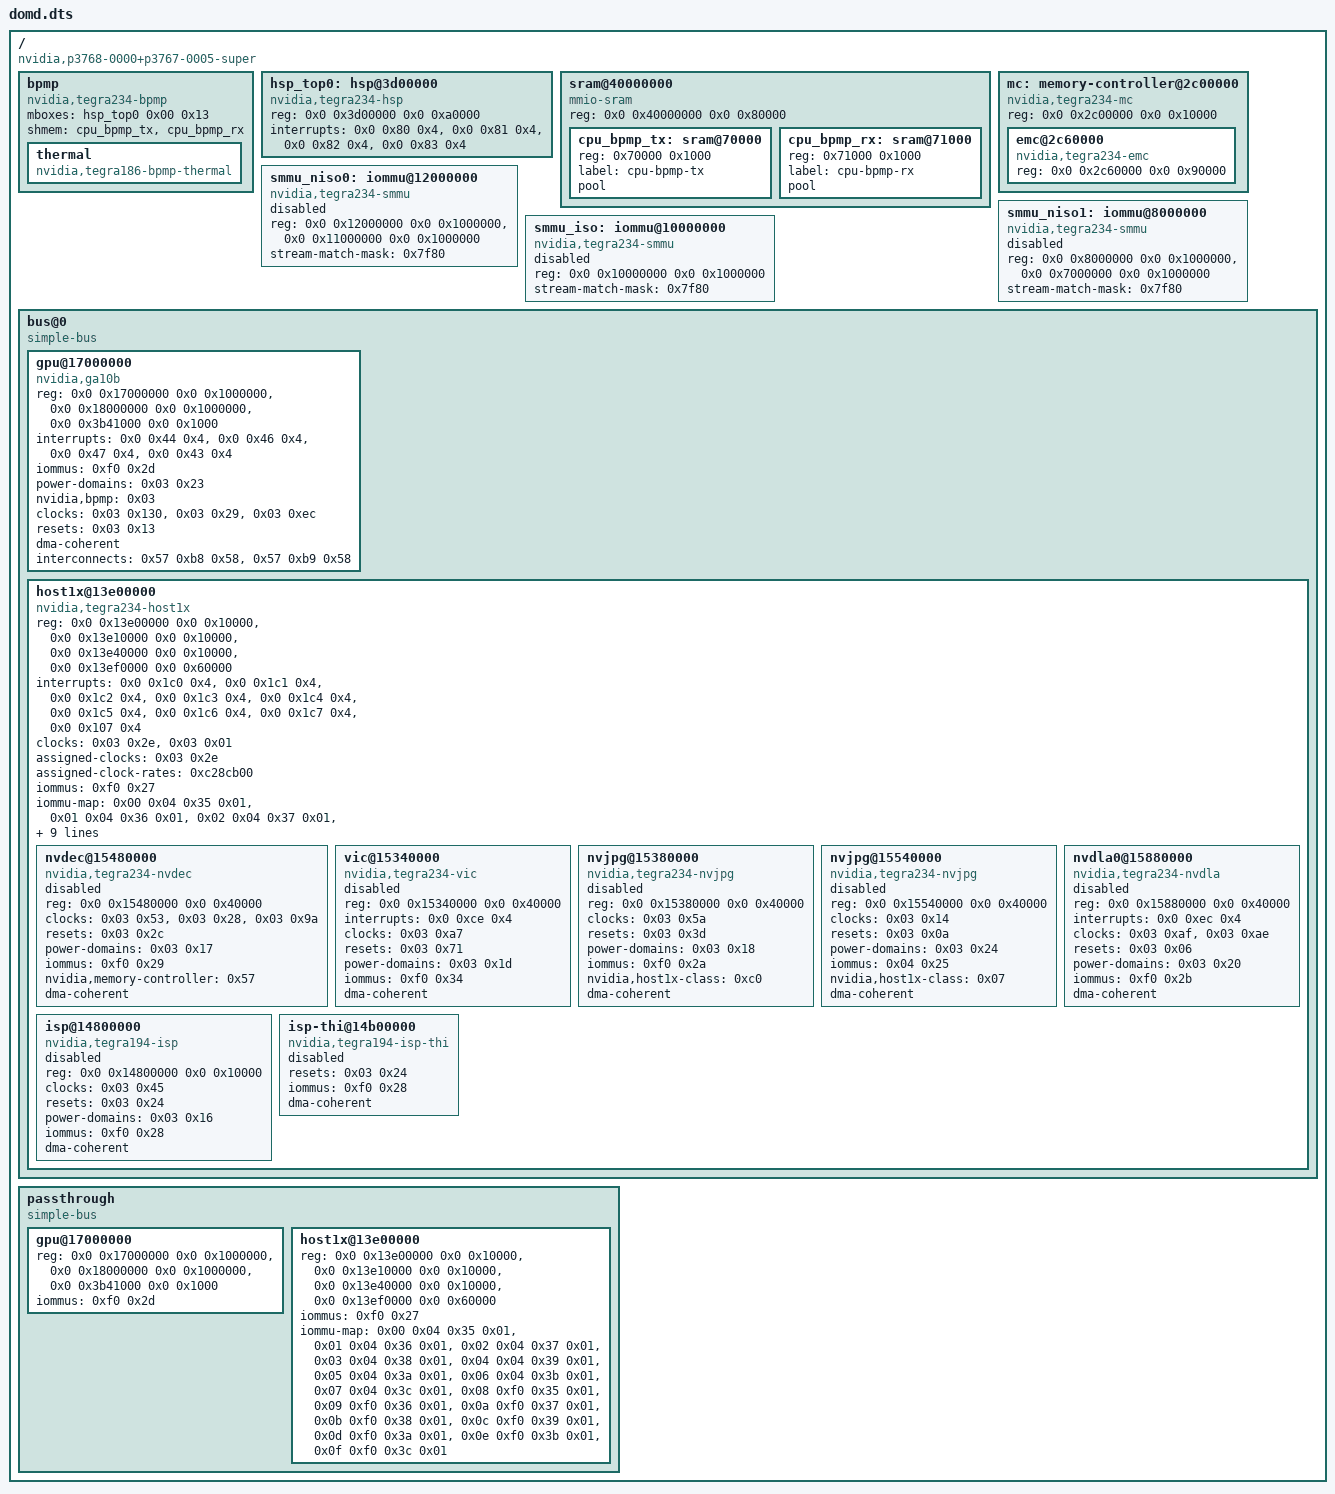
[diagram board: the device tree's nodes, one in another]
/dts-v1/;

/*
 * DomD Device Tree for GA10B GPU Passthrough — Jetson Orin Nano (tegra234)
 *
 * STRATEGY: Approach B — Stub BPMP
 *   Dom0 must pre-configure GPU (power-on, clocks, out-of-reset) before
 *   creating DomD.  GPU runs at whatever frequency Dom0 set, no DVFS.
 *
 * CHANGELOG:
 *   - Added /passthrough node (required by Xen libxl when
 *     passthrough = "enabled" is set in the domain config).
 *     Without this node xl create fails with FDT_ERR_NOTFOUND.
 */

/ {
	#address-cells = <2>;
	#size-cells = <2>;
	compatible = "nvidia,p3768-0000+p3767-0005-super",
	             "nvidia,p3767-0005",
	             "nvidia,tegra234";

	/* ================================================================
	 * BPMP — Stub / real depending on approach.
	 * Phandle 0x03 is referenced by GPU clocks/resets/power-domains.
	 * ================================================================ */
	bpmp: bpmp {
		compatible = "nvidia,tegra234-bpmp", "nvidia,tegra186-bpmp";
		#clock-cells = <1>;
		#reset-cells = <1>;
		#power-domain-cells = <1>;
		phandle = <0x03>;
		mboxes = <&hsp_top0 0x00 0x13>;
		shmem = <&cpu_bpmp_tx &cpu_bpmp_rx>;
		status = "okay";

		thermal {
			#thermal-sensor-cells = <1>;
			compatible = "nvidia,tegra186-bpmp-thermal";
		};
	};

	/* ================================================================
	 * HSP — doorbell for BPMP IPC
	 * Shared with Dom0; ensure Dom0 has released or proxied BPMP
	 * before DomD boots.
	 * ================================================================ */
	hsp_top0: hsp@3d00000 {
		compatible = "nvidia,tegra234-hsp", "nvidia,tegra194-hsp";
		reg = <0x0 0x3d00000 0x0 0xa0000>;
		interrupts = <0x0 0x80 0x4>,
		             <0x0 0x81 0x4>,
		             <0x0 0x82 0x4>,
		             <0x0 0x83 0x4>;
		interrupt-names = "shared0", "shared1", "shared2", "shared3";
		#mbox-cells = <2>;
		status = "okay";
	};

	/* ================================================================
	 * SRAM — IPC shared memory for BPMP
	 * ================================================================ */
	sram@40000000 {
		compatible = "mmio-sram";
		reg = <0x0 0x40000000 0x0 0x80000>;
		#address-cells = <1>;
		#size-cells = <1>;
		ranges = <0x0 0x0 0x40000000 0x80000>;

		cpu_bpmp_tx: sram@70000 {
			reg = <0x70000 0x1000>;
			label = "cpu-bpmp-tx";
			pool;
		};

		cpu_bpmp_rx: sram@71000 {
			reg = <0x71000 0x1000>;
			label = "cpu-bpmp-rx";
			pool;
		};
	};

	/* ================================================================
	 * Memory controller / EMC — GPU driver references these for
	 * bandwidth requests.  With stub BPMP the requests are no-ops.
	 * ================================================================ */
	mc: memory-controller@2c00000 {
		compatible = "nvidia,tegra234-mc";
		reg = <0x0 0x2c00000 0x0 0x10000>;
		#interconnect-cells = <1>;
		phandle = <0x57>;
		status = "okay";

		emc@2c60000 {
			compatible = "nvidia,tegra234-emc";
			reg = <0x0 0x2c60000 0x0 0x90000>;
			#interconnect-cells = <0>;
			phandle = <0x58>;
			status = "okay";
		};
	};

	/* ================================================================
	 * IOMMU / SMMU — reference-only, Xen owns the real hardware.
	 *
	 * These nodes MUST be disabled so the guest kernel does not
	 * probe them.  They exist only so that iommus phandle references
	 * in GPU and host1x nodes resolve correctly at DT parse time.
	 *
	 *   phandle 0x04  = NISO0 SMMU  @ 0x12000000
	 *   phandle 0xf0  = NISO1 SMMU  @ 0x08000000  (GPU SID 0x2d)
	 *   phandle 0x109 = ISO  SMMU   @ 0x10000000
	 * ================================================================ */
	smmu_niso0: iommu@12000000 {
		compatible = "nvidia,tegra234-smmu", "nvidia,smmu-500";
		reg = <0x0 0x12000000 0x0 0x1000000>,
		      <0x0 0x11000000 0x0 0x1000000>;
		#iommu-cells = <1>;
		stream-match-mask = <0x7f80>;
		phandle = <0x04>;
		status = "disabled";
	};

	smmu_niso1: iommu@8000000 {
		compatible = "nvidia,tegra234-smmu", "nvidia,smmu-500";
		reg = <0x0 0x8000000 0x0 0x1000000>,
		      <0x0 0x7000000 0x0 0x1000000>;
		#iommu-cells = <1>;
		stream-match-mask = <0x7f80>;
		phandle = <0xf0>;
		status = "disabled";
	};

	smmu_iso: iommu@10000000 {
		compatible = "nvidia,tegra234-smmu", "nvidia,smmu-500";
		reg = <0x0 0x10000000 0x0 0x1000000>;
		#iommu-cells = <1>;
		stream-match-mask = <0x7f80>;
		phandle = <0x109>;
		status = "disabled";
	};

	/* ================================================================
	 * Main bus
	 * ================================================================ */
	bus@0 {
		#address-cells = <2>;
		#size-cells = <2>;
		compatible = "simple-bus";
		ranges = <0x00 0x00 0x00 0x00 0x100 0x00>;

		/* ============================================================
		 * GPU — GA10B (Ampere) — PRIMARY PASSTHROUGH TARGET
		 *
		 * Register regions:
		 *   0x17000000  16 MB — GPU controller / GPC
		 *   0x18000000  16 MB — GPU Falcon / PMU
		 *   0x3b41000    4 KB — GPU scratch / priv ring
		 *
		 * Interrupts (SPI, so add 32):
		 *   68 (0x44) stall0  | 70 (0x46) stall1
		 *   71 (0x47) stall2  | 67 (0x43) nonstall
		 *
		 * IOMMU: SID 0x2d on NISO1 SMMU (phandle 0xf0)
		 * ============================================================ */
		gpu@17000000 {
			compatible = "nvidia,ga10b";
			reg = <0x0 0x17000000 0x0 0x1000000>,
			      <0x0 0x18000000 0x0 0x1000000>,
			      <0x0 0x3b41000  0x0 0x1000>;
			interrupts = <0x0 0x44 0x4>,
			             <0x0 0x46 0x4>,
			             <0x0 0x47 0x4>,
			             <0x0 0x43 0x4>;
			interrupt-names = "stall0", "stall1", "stall2", "nonstall";

			iommus = <0xf0 0x2d>;

			power-domains = <0x03 0x23>;
			nvidia,bpmp = <0x03>;
			clocks = <0x03 0x130>,
			         <0x03 0x29>,
			         <0x03 0xec>;
			clock-names = "sysclk", "gpc0clk", "gpc1clk";
			resets = <0x03 0x13>;
			reset-names = "gpu";

			dma-coherent;
			interconnect-names = "dma-mem", "write";
			interconnects = <0x57 0xb8 0x58>,
			                <0x57 0xb9 0x58>;

			#cooling-cells = <2>;
			status = "okay";
		};

		/* ============================================================
		 * Host1x — enable if DomD needs display or media offload.
		 *
		 * iommu-map covers per-context SIDs 0x35-0x3c on both
		 * NISO0 (0x04) and NISO1 (0xf0).  Add these SIDs to the
		 * Dom0 overlay xen,passthrough node if host1x children
		 * are enabled.
		 * ============================================================ */
		host1x@13e00000 {
			compatible = "nvidia,tegra234-host1x";
			reg = <0x0 0x13e00000 0x0 0x10000>,
			      <0x0 0x13e10000 0x0 0x10000>,
			      <0x0 0x13e40000 0x0 0x10000>,
			      <0x0 0x13ef0000 0x0 0x60000>;
			reg-names = "common", "hypervisor", "vm", "actmon";
			interrupts = <0x0 0x1c0 0x4>, <0x0 0x1c1 0x4>,
			             <0x0 0x1c2 0x4>, <0x0 0x1c3 0x4>,
			             <0x0 0x1c4 0x4>, <0x0 0x1c5 0x4>,
			             <0x0 0x1c6 0x4>, <0x0 0x1c7 0x4>,
			             <0x0 0x107 0x4>;
			interrupt-names = "syncpt0", "syncpt1", "syncpt2",
			                  "syncpt3", "syncpt4", "syncpt5",
			                  "syncpt6", "syncpt7", "host1x";
			clocks = <0x03 0x2e>, <0x03 0x01>;
			clock-names = "host1x", "actmon";
			assigned-clocks = <0x03 0x2e>;
			assigned-clock-rates = <0xc28cb00>;
			iommus = <0xf0 0x27>;
			iommu-map = <0x00 0x04 0x35 0x01>,
			            <0x01 0x04 0x36 0x01>,
			            <0x02 0x04 0x37 0x01>,
			            <0x03 0x04 0x38 0x01>,
			            <0x04 0x04 0x39 0x01>,
			            <0x05 0x04 0x3a 0x01>,
			            <0x06 0x04 0x3b 0x01>,
			            <0x07 0x04 0x3c 0x01>,
			            <0x08 0xf0 0x35 0x01>,
			            <0x09 0xf0 0x36 0x01>,
			            <0x0a 0xf0 0x37 0x01>,
			            <0x0b 0xf0 0x38 0x01>,
			            <0x0c 0xf0 0x39 0x01>,
			            <0x0d 0xf0 0x3a 0x01>,
			            <0x0e 0xf0 0x3b 0x01>,
			            <0x0f 0xf0 0x3c 0x01>;
			#address-cells = <2>;
			#size-cells = <2>;
			ranges = <0x0 0x14800000 0x0 0x14800000 0x0 0x2000000>,
			         <0x0 0x24700000 0x0 0x24700000 0x0 0x80000>;
			dma-coherent;
			interconnects = <0x57 0x16 0x58>;
			interconnect-names = "dma-mem";
			status = "okay";

			/* -- Media / compute engines — disabled by default --
			 * Enable only the engines DomD actually uses.
			 * Each needs its SID added to the Dom0 overlay too. */

			nvdec@15480000 {
				compatible = "nvidia,tegra234-nvdec";
				reg = <0x0 0x15480000 0x0 0x40000>;
				clocks = <0x03 0x53>, <0x03 0x28>, <0x03 0x9a>;
				clock-names = "nvdec", "fuse", "tsec_pka";
				resets = <0x03 0x2c>;
				reset-names = "nvdec";
				power-domains = <0x03 0x17>;
				iommus = <0xf0 0x29>;
				nvidia,memory-controller = <0x57>;
				dma-coherent;
				status = "disabled";
			};

			vic@15340000 {
				compatible = "nvidia,tegra234-vic";
				reg = <0x0 0x15340000 0x0 0x40000>;
				interrupts = <0x0 0xce 0x4>;
				clocks = <0x03 0xa7>;
				clock-names = "vic";
				resets = <0x03 0x71>;
				reset-names = "vic";
				power-domains = <0x03 0x1d>;
				iommus = <0xf0 0x34>;
				dma-coherent;
				status = "disabled";
			};

			nvjpg@15380000 {
				compatible = "nvidia,tegra234-nvjpg";
				reg = <0x0 0x15380000 0x0 0x40000>;
				clocks = <0x03 0x5a>;
				clock-names = "nvjpg";
				resets = <0x03 0x3d>;
				reset-names = "nvjpg";
				power-domains = <0x03 0x18>;
				iommus = <0xf0 0x2a>;
				nvidia,host1x-class = <0xc0>;
				dma-coherent;
				status = "disabled";
			};

			nvjpg@15540000 {
				compatible = "nvidia,tegra234-nvjpg";
				reg = <0x0 0x15540000 0x0 0x40000>;
				clocks = <0x03 0x14>;
				clock-names = "nvjpg";
				resets = <0x03 0x0a>;
				reset-names = "nvjpg";
				power-domains = <0x03 0x24>;
				iommus = <0x04 0x25>;
				nvidia,host1x-class = <0x07>;
				dma-coherent;
				status = "disabled";
			};

			nvdla0@15880000 {
				compatible = "nvidia,tegra234-nvdla";
				reg = <0x0 0x15880000 0x0 0x40000>;
				interrupts = <0x0 0xec 0x4>;
				clocks = <0x03 0xaf>, <0x03 0xae>;
				clock-names = "nvdla0", "nvdla0_flcn";
				resets = <0x03 0x06>;
				power-domains = <0x03 0x20>;
				iommus = <0xf0 0x2b>;
				dma-coherent;
				status = "disabled";
			};

			isp@14800000 {
				compatible = "nvidia,tegra194-isp";
				reg = <0x0 0x14800000 0x0 0x10000>;
				clocks = <0x03 0x45>;
				clock-names = "isp";
				resets = <0x03 0x24>;
				reset-names = "isp";
				power-domains = <0x03 0x16>;
				iommus = <0xf0 0x28>;
				dma-coherent;
				status = "disabled";
			};

			isp-thi@14b00000 {
				compatible = "nvidia,tegra194-isp-thi";
				resets = <0x03 0x24>;
				iommus = <0xf0 0x28>;
				dma-coherent;
				status = "disabled";
			};
		};
	};

	/* ================================================================
	 * /passthrough — REQUIRED by Xen libxl when the domain config
	 * sets passthrough = "enabled".
	 *
	 * libxl calls copy_partial_fdt() to copy this node verbatim into
	 * the constructed guest DTB.  If the node is absent, xl create
	 * fails with:
	 *   libxl_arm.c: Can't copy the node "/passthrough" from the
	 *   partial FDT — FDT_ERR_NOTFOUND
	 *
	 * Each child here must match a device node above by unit-address
	 * so Xen can correlate them.  The reg and iommus properties are
	 * what Xen actually uses to configure SMMU stream IDs and to
	 * restrict MMIO access; keep them in sync with the bus@0 nodes.
	 *
	 * Add a child entry for every device whose MMIO regions and/or
	 * DMA stream IDs you want Xen to exclusively assign to DomD.
	 * ================================================================ */
	passthrough {
		compatible = "simple-bus";
		ranges;
		#address-cells = <2>;
		#size-cells = <2>;

		/* GPU — GA10B
		 * MMIO: 0x17000000, 0x18000000, 0x3b41000
		 * SMMU SID 0x2d on NISO1 (phandle 0xf0) */
		gpu@17000000 {
			reg = <0x0 0x17000000 0x0 0x1000000>,
			      <0x0 0x18000000 0x0 0x1000000>,
			      <0x0 0x3b41000  0x0 0x1000>;
			iommus = <0xf0 0x2d>;
		};

		/* Host1x
		 * MMIO: 0x13e00000 (4 regions)
		 * SMMU SID 0x27 on NISO1 + context SIDs 0x35-0x3c
		 * on both NISO0 and NISO1 */
		host1x@13e00000 {
			reg = <0x0 0x13e00000 0x0 0x10000>,
			      <0x0 0x13e10000 0x0 0x10000>,
			      <0x0 0x13e40000 0x0 0x10000>,
			      <0x0 0x13ef0000 0x0 0x60000>;
			iommus = <0xf0 0x27>;
			iommu-map = <0x00 0x04 0x35 0x01>,
			            <0x01 0x04 0x36 0x01>,
			            <0x02 0x04 0x37 0x01>,
			            <0x03 0x04 0x38 0x01>,
			            <0x04 0x04 0x39 0x01>,
			            <0x05 0x04 0x3a 0x01>,
			            <0x06 0x04 0x3b 0x01>,
			            <0x07 0x04 0x3c 0x01>,
			            <0x08 0xf0 0x35 0x01>,
			            <0x09 0xf0 0x36 0x01>,
			            <0x0a 0xf0 0x37 0x01>,
			            <0x0b 0xf0 0x38 0x01>,
			            <0x0c 0xf0 0x39 0x01>,
			            <0x0d 0xf0 0x3a 0x01>,
			            <0x0e 0xf0 0x3b 0x01>,
			            <0x0f 0xf0 0x3c 0x01>;
		};
	};

	/* ================================================================
	 * Thermal zones — commented out; requires working BPMP sensor.
	 * Uncomment when using Approach A (real BPMP).
	 * ================================================================ */
	/*
	thermal-zones {
		gpu-thermal {
			polling-delay = <1000>;
			polling-delay-passive = <1000>;
			thermal-sensors = <&bpmp 1>;
			status = "okay";

			trips {
				gpu-sw-slowdown {
					temperature = <98500>;
					hysteresis = <5000>;
					type = "passive";
				};
				gpu-sw-shutdown {
					temperature = <104500>;
					hysteresis = <0>;
					type = "critical";
				};
				hot-surface {
					temperature = <70000>;
					hysteresis = <8000>;
					type = "passive";
				};
			};
		};
	};
	*/
};
